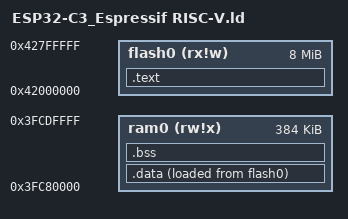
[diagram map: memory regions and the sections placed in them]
/*
 * This file was auto-generated by microzig
 *
 * Target CPU:  Espressif RISC-V
 * Target Chip: ESP32-C3
 */

ENTRY(microzig_main);

MEMORY
{
  flash0 (rx!w) : ORIGIN = 0x42000000, LENGTH = 0x00800000
  ram0   (rw!x) : ORIGIN = 0x3FC80000, LENGTH = 0x00060000
}

SECTIONS
{
  .text :
  {
     KEEP(*(microzig_flash_start))
     *(.text*)
  } > flash0

  .data :
  {
     microzig_data_start = .;
     *(.rodata*)
     *(.data*)
     microzig_data_end = .;
  } > ram0 AT> flash0

  .bss (NOLOAD) :
  {
      microzig_bss_start = .;
      *(.bss*)
      microzig_bss_end = .;
  } > ram0

  microzig_data_load_start = LOADADDR(.data);
}
